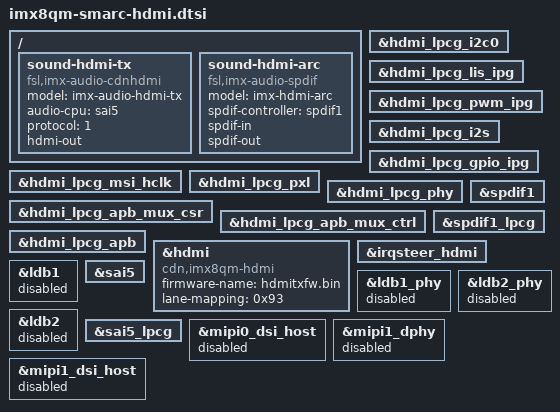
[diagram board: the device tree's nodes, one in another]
/*
 * Copyright 2021 EMBEDIAN, INC.
 */

/ {
	sound-hdmi-tx {
		compatible = "fsl,imx-audio-cdnhdmi";
		model = "imx-audio-hdmi-tx";
		audio-cpu = <&sai5>;
		protocol = <1>;
		hdmi-out;
	};

	sound-hdmi-arc {
		compatible = "fsl,imx-audio-spdif";
		model = "imx-hdmi-arc";
		spdif-controller = <&spdif1>;
		spdif-in;
		spdif-out;
	};
};

&hdmi_lpcg_i2c0 {
	status = "okay";
};

&hdmi_lpcg_lis_ipg {
	status = "okay";
};

&hdmi_lpcg_pwm_ipg {
	status = "okay";
};

&hdmi_lpcg_i2s {
	status = "okay";
};

&hdmi_lpcg_gpio_ipg {
	status = "okay";
};

&hdmi_lpcg_msi_hclk {
	status = "okay";
};

&hdmi_lpcg_pxl {
	status = "okay";
};

&hdmi_lpcg_phy {
	status = "okay";
};

&hdmi_lpcg_apb_mux_csr {
	status = "okay";
};

&hdmi_lpcg_apb_mux_ctrl {
	status = "okay";
};

&hdmi_lpcg_apb {
	status = "okay";
};

&hdmi {
	compatible = "cdn,imx8qm-hdmi";
	firmware-name = "hdmitxfw.bin";
	lane-mapping = <0x93>;
	status = "okay";
};

&spdif1 {
	status = "okay";
};

&spdif1_lpcg {
	status = "okay";
};

&irqsteer_hdmi {
	status = "okay";
};

&ldb1 {
	status = "disabled";
};

&ldb1_phy {
	status = "disabled";
};

&ldb2_phy {
	status = "disabled";
};

&ldb2 {
	status = "disabled";
};

&sai5 {
	status = "okay";
};

&sai5_lpcg {
	status = "okay";
};

&mipi0_dsi_host {
	status = "disabled";
};

&mipi1_dphy {
	status = "disabled";
};

&mipi1_dsi_host {
	status = "disabled";
};

&mipi1_dphy {
	status = "disabled";
};
